# Apollo register map
Vendor: Ambiq Micro; Series: Apollo; File version: 1.0
Low-power ARM Cortex-M4 MCU from Ambiq Micro
CPU: CM4 r1p0, little endian, MPU, FPU, 3 interrupt priority bits
Registers are 32-bit, read-write, reset 0x0 unless marked. A register's access mark holds for its fields unless they carry their own. Offsets are from the block's base; lines under a group give offsets from that group; [hi:lo] are bit positions; {n}, {i} and the like mark numbered series; 'fields as' and 'values as' point back to an identical list; <NAME> marks a mode.

## Memory map
0x40000000 RSTGEN size 0x210 — MCU Reset Generator
0x40004000 CLKGEN size 0x110 — Clock Generator
0x40008000 CTIMER size 0x210 — Counter/Timer
0x4000C000 VCOMP size 0x210 — Voltage Comparator
0x40010000 GPIO size 0x220 — General Purpose IO
0x4001C000 UART size 0x48 — Serial UART
0x40020000 MCUCTRL size 0x254 — MCU Miscellaneous Control Logic
0x40024000 WDT size 0x210 — Watchdog Timer
0x50000000 IOSLAVE size 0x220 — I2C/SPI Slave
0x50004000 IOMSTR0 size 0x210 — I2C/SPI Master
0x50005000 IOMSTR1 size 0x210
0x50008000 ADC size 0x210 — Analog Digital Converter Control

## Interrupts
0 BROWNOUT (MCUCTRL)
1 WDT
2 CLKGEN
3 VCOMP
4 IOSLAVE
5 IOSLAVEACC (IOSLAVE)
6 IOMSTR0
7 IOMSTR1
8 ADC
9 GPIO
10 CTIMER
11 UART

## VCOMP — Voltage Comparator
Base 0x4000C000
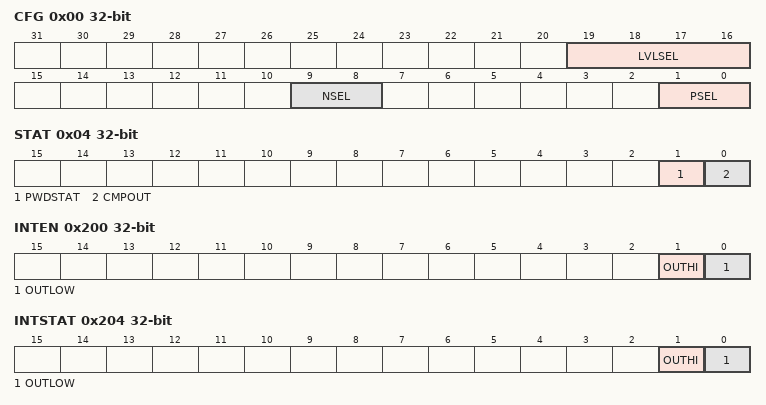
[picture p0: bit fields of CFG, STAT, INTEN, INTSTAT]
0x00 CFG — Configuration Register
  [19:16] LVLSEL — When the reference input NSEL is set to NSEL_DAC, this bitfield selects the voltage level for the negative input to the comparator.
    0=0P58V (Set Reference input to 0.58 Volts.); 1=0P77V (Set Reference input to 0.77 Volts.); 2=0P97V (Set Reference input to 0.97 Volts.); 3=1P16V (Set Reference input to 1.16 Volts.); 4=1P35V (Set Reference input to 1.35 Volts.); 5=1P55V (Set Reference input to 1.55 Volts.); 6=1P74V (Set Reference input to 1.74 Volts.); 7=1P93V (Set Reference input to 1.93 Volts.); 8=2P13V (Set Reference input to 2.13 Volts.); 9=2P32V (Set Reference input to 2.32 Volts.); 10=2P51V (Set Reference input to 2.51 Volts.); 11=2P71V (Set Reference input to 2.71 Volts.); 12=2P90V (Set Reference input to 2.90 Volts.); 13=3P09V (Set Reference input to 3.09 Volts.); 14=3P29V (Set Reference input to 3.29 Volts.); 15=3P48V (Set Reference input to 3.48 Volts.)
  [9:8] NSEL — This bitfield selects the negative input to the comparator.
    0=VREFEXT1 (Use external reference 1 for reference input.); 1=VREFEXT2 (Use external reference 2 for reference input.); 3=VREFEXT3 (Use external reference 3 for reference input.)
  [1:0] PSEL — This bitfield selects the positive input to the comparator.
    0=VDDADJ (Use VDDADJ for the positive input.); 1=VTEMP (Use the temperature sensor output for the positive input.); 2=VEXT1 (Use external voltage 1 for positive input.); 3=VEXT2 (Use external voltage 1 for positive input.)
0x04 STAT — Status Register
  [1] PWDSTAT — This bit indicates the power down state of the voltage comparator.
    1=POWERED_DOWN (The voltage comparator is powered down.)
  [0] CMPOUT — This bit is 1 if the positive input of the comparator is greater than the negative input.
    0=VOUT_LOW (The negative input of the comparator is greater than the positive input.); 1=VOUT_HIGH (The positive input of the comparator is greater than the negative input.)
0x08 PWDKEY — Key Register for Powering Down the Voltage Comparator
  [31:0] PWDKEY — Key register value.
    55=Key
0x200 INTEN — Voltage Comparator Interrupt registers: Enable
  [1] OUTHI — This bit is the vcompout high interrupt.
  [0] OUTLOW — This bit is the vcompout low interrupt.
0x204 INTSTAT — Voltage Comparator Interrupt registers: Status
  fields as INTEN
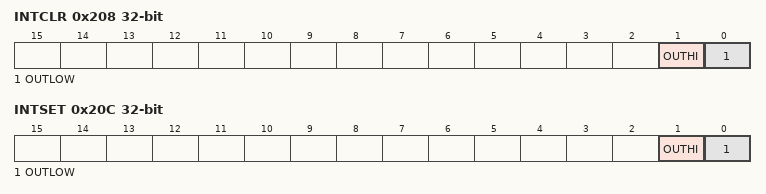
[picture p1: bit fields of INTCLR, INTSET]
0x208 INTCLR — Voltage Comparator Interrupt registers: Clear
  fields as INTEN
0x20C INTSET — Voltage Comparator Interrupt registers: Set
  fields as INTEN

## Licence text in the file
Copyright (c) 2015, Ambiq Micro. All rights reserved. . Redistribution and use in source and binary forms, with or without modification, are permitted provided that the following conditions are met: . 1. Redistributions of source code must retain the above copyright notice, this list of conditions and the following disclaimer. . 2. Redistributions in binary form must reproduce the above copyright notice, this list of conditions and the following disclaimer in the documentation and/or other materials provided with the distribution. . 3. Neither the name of the copyright holder nor the names of its contributors may be used to endorse or promote products derived from this software without specific prior written permission. . THIS SOFTWARE IS PROVIDED BY THE COPYRIGHT HOLDERS AND CONTRIBUTORS "AS IS" AND ANY EXPRESS OR IMPLIED WARRANTIES, INCLUDING, BUT NOT LIMITED TO, THE. IMPLIED WARRANTIES OF MERCHANTABILITY AND FITNESS FOR A PARTICULAR PURPOSE. ARE DISCLAIMED. IN NO EVENT SHALL THE COPYRIGHT HOLDER OR CONTRIBUTORS BE. LIABLE FOR ANY DIRECT, INDIRECT, INCIDENTAL, SPECIAL, EXEMPLARY, OR. CONSEQUENTIAL DAMAGES (INCLUDING, BUT NOT LIMITED TO, PROCUREMENT OF. SUBSTITUTE GOODS OR SERVICES; LOSS OF USE, DATA, OR PROFITS; OR BUSINESS. INTERRUPTION) HOWEVER CAUSED AND ON ANY THEORY OF LIABILITY, WHETHER IN. CONTRACT, STRICT LIABILITY, OR TORT (INCLUDING NEGLIGENCE OR OTHERWISE). ARISING IN ANY WAY OUT OF THE USE OF THIS SOFTWARE, EVEN IF ADVISED OF THE. POSSIBILITY OF SUCH DAMAGE.
